# LPC11Uxx register map
File version: 7
CPU: CM0 r0p0, little endian, no MPU, no FPU, 2 interrupt priority bits
Registers are 32-bit, read-write, reset 0x0 unless marked. A register's access mark holds for its fields unless they carry their own. Offsets are from the block's base; [hi:lo] are bit positions; {n}, {i} and the like mark numbered series; 'fields as' and 'values as' point back to an identical list.

## IOCON — I/O configuration Modification
Base 0x40044000
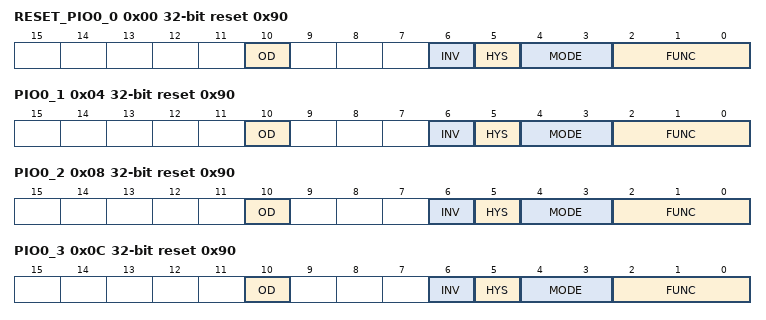
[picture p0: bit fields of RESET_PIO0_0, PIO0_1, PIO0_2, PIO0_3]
0x00 RESET_PIO0_0 reset 0x90 — I/O configuration for pin RESET/PIO0_0
  [10] OD — Open-drain mode.
    0=DISABLED; 1=OPEN_DRAIN (Open-drain mode enabled. This is not a true open-drain mode.)
  [6] INV — Invert input
    0=NOT_INVERTED (Input not inverted (HIGH on pin reads as 1, LOW on pin reads as 0).); 1=INVERTED (Input inverted (HIGH on pin reads as 0, LOW on pin reads as 1).)
  [5] HYS — Hysteresis.
    0=DISABLED; 1=ENABLED
  [4:3] MODE — Selects function mode (on-chip pull-up/pull-down resistor control).
    0=FLOATING (Inactive (no pull-down/pull-up resistor enabled).); 1=PULL_DOWN (Pull-down resistor enabled.); 2=PULL_UP (Pull-up resistor enabled.); 3=REPEATER (Repeater mode.)
  [2:0] FUNC — Selects pin function. Values 0x2 to 0x7 are reserved.
    0=RESET; 1=PIO0_0
0x04 PIO0_1 reset 0x90 — I/O configuration for pin PIO0_1/CLKOUT/CT32B0_MAT2/USB_FTOGGLE
  [10] OD — Open-drain mode.
    values as RESET_PIO0_0.OD
  [6] INV — Invert input
    values as RESET_PIO0_0.INV
  [5] HYS — Hysteresis.
    0=DISABLED; 1=ENABLED
  [4:3] MODE — Selects function mode (on-chip pull-up/pull-down resistor control).
    values as RESET_PIO0_0.MODE
  [2:0] FUNC — Selects pin function. Values 0x4 to 0x7 are reserved.
    0=PIO0_1; 1=CLKOUT; 2=CT32B0_MAT2; 3=USB_FTOGGLE
0x08 PIO0_2 reset 0x90 — I/O configuration for pin PIO0_2/SSEL0/CT16B0_CAP0
  [10] OD — Open-drain mode.
    values as RESET_PIO0_0.OD
  [6] INV — Invert input
    values as RESET_PIO0_0.INV
  [5] HYS — Hysteresis.
    0=DISABLED; 1=ENABLED
  [4:3] MODE — Selects function mode (on-chip pull-up/pull-down resistor control).
    values as RESET_PIO0_0.MODE
  [2:0] FUNC — Selects pin function. Values 0x3 to 0x7 are reserved.
    0=PIO0_2; 1=SSEL0; 2=CT16B0_CAP0
0x0C PIO0_3 reset 0x90 — I/O configuration for pin PIO0_3/USB_VBUS
  [10] OD — Open-drain mode.
    values as RESET_PIO0_0.OD
  [6] INV — Invert input
    values as RESET_PIO0_0.INV
  [5] HYS — Hysteresis.
    0=DISABLED; 1=ENABLED
  [4:3] MODE — Selects function mode (on-chip pull-up/pull-down resistor control).
    values as RESET_PIO0_0.MODE
  [2:0] FUNC — Selects pin function. Values 0x2 to 0x7 are reserved.
    0=PIO0_3; 1=USB_VBUS
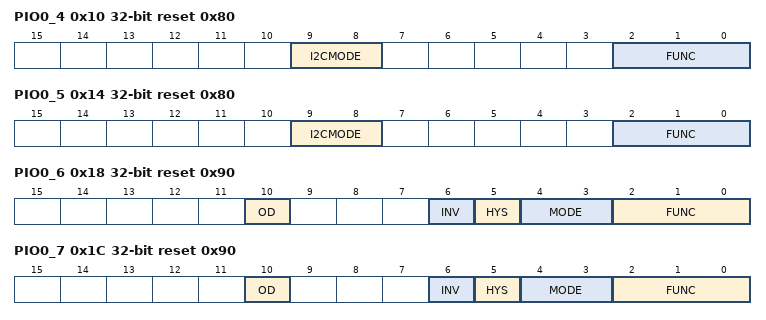
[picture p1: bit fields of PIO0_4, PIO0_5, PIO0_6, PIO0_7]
0x10 PIO0_4 reset 0x80 — I/O configuration for pin PIO0_4/SCL
  [9:8] I2CMODE — Selects I2C mode (see Section 7.3.8). Select Standard mode (I2CMODE = 00, default) or Standard I/O functionality (I2CMODE = 01) if the pin function is GPIO (FUNC = 000).
    0=STANDARD_MODE (Standard mode/ Fast-mode I2C.); 1=STANDARD_IO (Standard I/O functionality); 2=FAST_MODE_PLUS (Fast-mode Plus I2C)
  [2:0] FUNC — Selects pin function. Values 0x2 to 0x7 are reserved.
    0=PIO0_4 (PIO0_4 (open-drain pin).); 1=I2C_SCL (I2C SCL (open-drain pin).)
0x14 PIO0_5 reset 0x80 — I/O configuration for pin PIO0_5/SDA
  [9:8] I2CMODE — Selects I2C mode (see Section 7.3.8). Select Standard mode (I2CMODE = 00, default) or Standard I/O functionality (I2CMODE = 01) if the pin function is GPIO (FUNC = 000).
    values as PIO0_4.I2CMODE
  [2:0] FUNC — Selects pin function. Values 0x2 to 0x7 are reserved.
    0=PIO0_5 (PIO0_5 (open-drain pin).); 1=I2C_SDA (I2C SDA (open-drain pin).)
0x18 PIO0_6 reset 0x90 — I/O configuration for pin PIO0_6/USB_CONNECT/SCK0
  [10] OD — Open-drain mode.
    values as RESET_PIO0_0.OD
  [6] INV — Invert input
    values as RESET_PIO0_0.INV
  [5] HYS — Hysteresis.
    0=DISABLED; 1=ENABLED
  [4:3] MODE — Selects function mode (on-chip pull-up/pull-down resistor control).
    values as RESET_PIO0_0.MODE
  [2:0] FUNC — Selects pin function. Values 0x3 to 0x7 are reserved.
    0=PIO0_6; 1=USB_CONNECT; 2=SCK0
0x1C PIO0_7 reset 0x90 — I/O configuration for pin PIO0_7/CTS
  [10] OD — Open-drain mode.
    values as RESET_PIO0_0.OD
  [6] INV — Invert input
    values as RESET_PIO0_0.INV
  [5] HYS — Hysteresis.
    0=DISABLED; 1=ENABLED
  [4:3] MODE — Selects function mode (on-chip pull-up/pull-down resistor control).
    values as RESET_PIO0_0.MODE
  [2:0] FUNC — Selects pin function. Values 0x2 to 0x7 are reserved.
    0=PIO0_7; 1=CTS
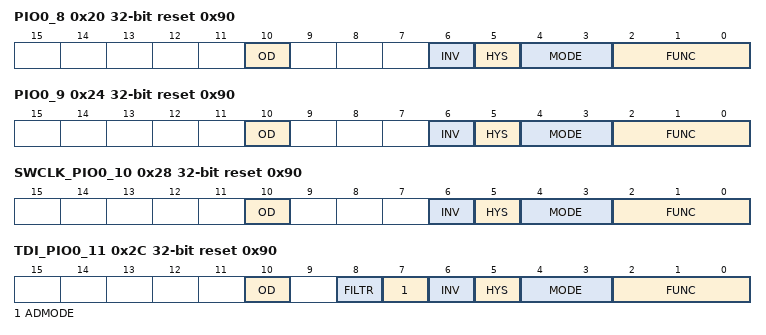
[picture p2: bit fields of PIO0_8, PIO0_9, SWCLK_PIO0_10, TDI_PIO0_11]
0x20 PIO0_8 reset 0x90 — I/O configuration for pin PIO0_8/MISO0/CT16B0_MAT0
  [10] OD — Open-drain mode.
    values as RESET_PIO0_0.OD
  [6] INV — Invert input
    values as RESET_PIO0_0.INV
  [5] HYS — Hysteresis.
    0=DISABLED; 1=ENABLED
  [4:3] MODE — Selects function mode (on-chip pull-up/pull-down resistor control).
    values as RESET_PIO0_0.MODE
  [2:0] FUNC — Selects pin function. Values 0x3 to 0x7 are reserved.
    0=PIO0_8; 1=MISO0; 2=CT16B0_MAT0
0x24 PIO0_9 reset 0x90 — I/O configuration for pin PIO0_9/MOSI0/CT16B0_MAT1
  [10] OD — Open-drain mode.
    values as RESET_PIO0_0.OD
  [6] INV — Invert input
    values as RESET_PIO0_0.INV
  [5] HYS — Hysteresis.
    0=DISABLED; 1=ENABLED
  [4:3] MODE — Selects function mode (on-chip pull-up/pull-down resistor control).
    values as RESET_PIO0_0.MODE
  [2:0] FUNC — Selects pin function. Values 0x3 to 0x7 are reserved.
    0=PIO0_9; 1=MOSI0; 2=CT16B0_MAT1
0x28 SWCLK_PIO0_10 reset 0x90 — I/O configuration for pin SWCLK/PIO0_10/ SCK0/CT16B0_MAT2
  [10] OD — Open-drain mode.
    values as RESET_PIO0_0.OD
  [6] INV — Invert input
    values as RESET_PIO0_0.INV
  [5] HYS — Hysteresis.
    0=DISABLED; 1=ENABLED
  [4:3] MODE — Selects function mode (on-chip pull-up/pull-down resistor control).
    values as RESET_PIO0_0.MODE
  [2:0] FUNC — Selects pin function. Values 0x4 to 0x7 are reserved.
    0=SWCLK; 1=PIO0_10; 2=SCK0; 3=CT16B0_MAT2
0x2C TDI_PIO0_11 reset 0x90 — I/O configuration for pin TDI/PIO0_11/AD0/CT32B0_MAT3
  [10] OD — Open-drain mode.
    values as RESET_PIO0_0.OD
  [8] FILTR — Selects 10 ns input glitch filter.
    0=ENABLED (Filter enabled.); 1=DISABLED (Filter disabled.)
  [7] ADMODE — Selects Analog/Digital mode.
    0=ANALOG (Analog input mode.); 1=DIGITAL (Digital functional mode.)
  [6] INV — Invert input
    values as RESET_PIO0_0.INV
  [5] HYS — Hysteresis.
    0=DISABLED; 1=ENABLED
  [4:3] MODE — Selects function mode (on-chip pull-up/pull-down resistor control).
    values as RESET_PIO0_0.MODE
  [2:0] FUNC — Selects pin function. Values 0x4 to 0x7 are reserved.
    0=TDI; 1=PIO0_11; 2=AD0; 3=CT32B0_MAT3
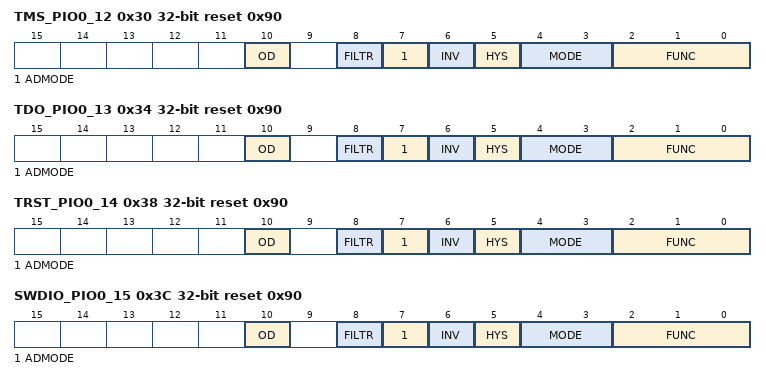
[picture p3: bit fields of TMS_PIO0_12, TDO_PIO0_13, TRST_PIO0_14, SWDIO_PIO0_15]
0x30 TMS_PIO0_12 reset 0x90 — I/O configuration for pin TMS/PIO0_12/AD1/CT32B1_CAP0
  [10] OD — Open-drain mode.
    values as RESET_PIO0_0.OD
  [8] FILTR — Selects 10 ns input glitch filter.
    0=ENABLED (Filter enabled.); 1=DISABLED (Filter disabled.)
  [7] ADMODE — Selects Analog/Digital mode.
    values as TDI_PIO0_11.ADMODE
  [6] INV — Invert input
    values as RESET_PIO0_0.INV
  [5] HYS — Hysteresis.
    0=DISABLED; 1=ENABLED
  [4:3] MODE — Selects function mode (on-chip pull-up/pull-down resistor control).
    values as RESET_PIO0_0.MODE
  [2:0] FUNC — Selects pin function. Values 0x4 to 0x7 are reserved.
    0=TMS; 1=PIO0_12; 2=AD1; 3=CT32B1_CAP0
0x34 TDO_PIO0_13 reset 0x90 — I/O configuration for pin TDO/PIO0_13/AD2/CT32B1_MAT0
  [10] OD — Open-drain mode.
    values as RESET_PIO0_0.OD
  [8] FILTR — Selects 10 ns input glitch filter.
    0=ENABLED (Filter enabled.); 1=DISABLED (Filter disabled.)
  [7] ADMODE — Selects Analog/Digital mode.
    values as TDI_PIO0_11.ADMODE
  [6] INV — Invert input
    values as RESET_PIO0_0.INV
  [5] HYS — Hysteresis.
    0=DISABLED; 1=ENABLED
  [4:3] MODE — Selects function mode (on-chip pull-up/pull-down resistor control).
    values as RESET_PIO0_0.MODE
  [2:0] FUNC — Selects pin function. Values 0x4 to 0x7 are reserved.
    0=TDO; 1=PIO0_13; 2=AD2; 3=CT32B1_MAT0
0x38 TRST_PIO0_14 reset 0x90 — I/O configuration for pin TRST/PIO0_14/AD3/CT32B1_MAT1
  [10] OD — Open-drain mode.
    values as RESET_PIO0_0.OD
  [8] FILTR — Selects 10 ns input glitch filter.
    0=ENABLED (Filter enabled.); 1=DISABLED (Filter disabled.)
  [7] ADMODE — Selects Analog/Digital mode.
    values as TDI_PIO0_11.ADMODE
  [6] INV — Invert input
    values as RESET_PIO0_0.INV
  [5] HYS — Hysteresis.
    0=DISABLED; 1=ENABLED
  [4:3] MODE — Selects function mode (on-chip pull-up/pull-down resistor control).
    values as RESET_PIO0_0.MODE
  [2:0] FUNC — Selects pin function. Values 0x4 to 0x7 are reserved.
    0=TRST; 1=PIO0_14; 2=AD3; 3=CT32B1_MAT1
0x3C SWDIO_PIO0_15 reset 0x90 — I/O configuration for pin SWDIO/PIO0_15/AD4/CT32B1_MAT2
  [10] OD — Open-drain mode.
    values as RESET_PIO0_0.OD
  [8] FILTR — Selects 10 ns input glitch filter.
    0=ENABLED (Filter enabled.); 1=DISABLED (Filter disabled.)
  [7] ADMODE — Selects Analog/Digital mode.
    values as TDI_PIO0_11.ADMODE
  [6] INV — Invert input
    values as RESET_PIO0_0.INV
  [5] HYS — Hysteresis.
    0=DISABLED; 1=ENABLED
  [4:3] MODE — Selects function mode (on-chip pull-up/pull-down resistor control).
    values as RESET_PIO0_0.MODE
  [2:0] FUNC — Selects pin function. Values 0x4 to 0x7 are reserved.
    0=SWDIO; 1=PIO0_15; 2=AD4; 3=CT32B1_MAT2
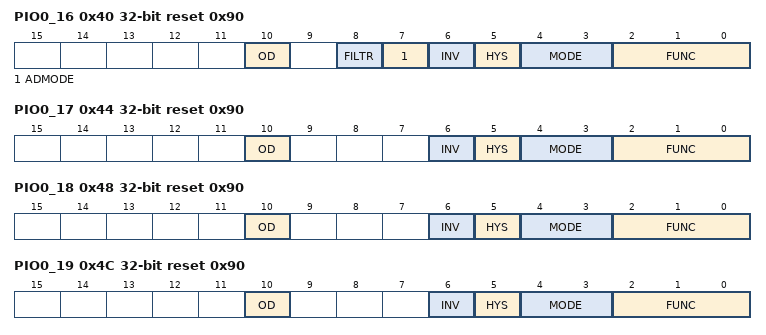
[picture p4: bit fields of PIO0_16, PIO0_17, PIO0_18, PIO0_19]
0x40 PIO0_16 reset 0x90 — I/O configuration for pin PIO0_16/AD5/CT32B1_MAT3/ WAKEUP
  [10] OD — Open-drain mode.
    values as RESET_PIO0_0.OD
  [8] FILTR — Selects 10 ns input glitch filter.
    0=ENABLED (Filter enabled.); 1=DISABLED (Filter disabled.)
  [7] ADMODE — Selects Analog/Digital mode.
    values as TDI_PIO0_11.ADMODE
  [6] INV — Invert input
    values as RESET_PIO0_0.INV
  [5] HYS — Hysteresis.
    0=DISABLED; 1=ENABLED
  [4:3] MODE — Selects function mode (on-chip pull-up/pull-down resistor control).
    values as RESET_PIO0_0.MODE
  [2:0] FUNC — Selects pin function. This pin functions as WAKEUP pin if the LPC11Uxx is in Deep power-down mode regardless of the value of FUNC. Values 0x3 to 0x7 are reserved.
    0=PIO0_16; 1=AD5; 2=CT32B1_MAT3
0x44 PIO0_17 reset 0x90 — I/O configuration for pin PIO0_17/RTS/CT32B0_CAP0/SCLK
  [10] OD — Open-drain mode.
    values as RESET_PIO0_0.OD
  [6] INV — Invert input
    values as RESET_PIO0_0.INV
  [5] HYS — Hysteresis.
    0=DISABLED; 1=ENABLED
  [4:3] MODE — Selects function mode (on-chip pull-up/pull-down resistor control).
    values as RESET_PIO0_0.MODE
  [2:0] FUNC — Selects pin function. Values 0x4 to 0x7 are reserved.
    0=PIO0_17; 1=RTS; 2=CT32B0_CAP0; 3=SCLK_UART_SYNCHRONO (SCLK (UART synchronous clock).)
0x48 PIO0_18 reset 0x90 — I/O configuration for pin PIO0_18/RXD/CT32B0_MAT0
  [10] OD — Open-drain mode.
    values as RESET_PIO0_0.OD
  [6] INV — Invert input
    values as RESET_PIO0_0.INV
  [5] HYS — Hysteresis.
    0=DISABLED; 1=ENABLED
  [4:3] MODE — Selects function mode (on-chip pull-up/pull-down resistor control).
    values as RESET_PIO0_0.MODE
  [2:0] FUNC — Selects pin function. Values 0x3 to 0x7 are reserved.
    0=PIO0_18; 1=RXD; 2=CT32B0_MAT0
0x4C PIO0_19 reset 0x90 — I/O configuration for pin PIO0_19/TXD/CT32B0_MAT1
  [10] OD — Open-drain mode.
    values as RESET_PIO0_0.OD
  [6] INV — Invert input
    values as RESET_PIO0_0.INV
  [5] HYS — Hysteresis.
    0=DISABLED; 1=ENABLED
  [4:3] MODE — Selects function mode (on-chip pull-up/pull-down resistor control).
    values as RESET_PIO0_0.MODE
  [2:0] FUNC — Selects pin function. Values 0x3 to 0x7 are reserved.
    0=PIO0_19; 1=TXD; 2=CT32B0_MAT1
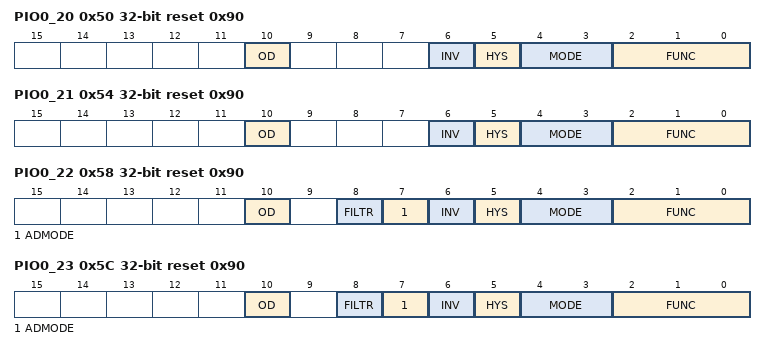
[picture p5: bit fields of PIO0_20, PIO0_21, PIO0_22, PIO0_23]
0x50 PIO0_20 reset 0x90 — I/O configuration for pin PIO0_20/CT16B1_CAP0
  [10] OD — Open-drain mode.
    values as RESET_PIO0_0.OD
  [6] INV — Invert input
    values as RESET_PIO0_0.INV
  [5] HYS — Hysteresis.
    0=DISABLED; 1=ENABLED
  [4:3] MODE — Selects function mode (on-chip pull-up/pull-down resistor control).
    values as RESET_PIO0_0.MODE
  [2:0] FUNC — Selects pin function. Values 0x2 to 0x7 are reserved.
    0=PIO0_20; 1=CT16B1_CAP0
0x54 PIO0_21 reset 0x90 — I/O configuration for pin PIO0_21/CT16B1_MAT0/MOSI1
  [10] OD — Open-drain mode.
    values as RESET_PIO0_0.OD
  [6] INV — Invert input
    values as RESET_PIO0_0.INV
  [5] HYS — Hysteresis.
    0=DISABLED; 1=ENABLED
  [4:3] MODE — Selects function mode (on-chip pull-up/pull-down resistor control).
    values as RESET_PIO0_0.MODE
  [2:0] FUNC — Selects pin function. Values 0x3 to 0x7 are reserved.
    0=PIO0_21; 1=CT16B1_MAT0; 2=MOSI1
0x58 PIO0_22 reset 0x90 — I/O configuration for pin PIO0_22/AD6/CT16B1_MAT1/MISO1
  [10] OD — Open-drain mode.
    values as RESET_PIO0_0.OD
  [8] FILTR — Selects 10 ns input glitch filter.
    0=ENABLED (Filter enabled.); 1=DISABLED (Filter disabled.)
  [7] ADMODE — Selects Analog/Digital mode.
    values as TDI_PIO0_11.ADMODE
  [6] INV — Invert input
    values as RESET_PIO0_0.INV
  [5] HYS — Hysteresis.
    0=DISABLED; 1=ENABLED
  [4:3] MODE — Selects function mode (on-chip pull-up/pull-down resistor control).
    values as RESET_PIO0_0.MODE
  [2:0] FUNC — Selects pin function. Values 0x4 to 0x7 are reserved.
    0=PIO0_22; 1=AD6; 2=CT16B1_MAT1; 3=MISO1
0x5C PIO0_23 reset 0x90 — I/O configuration for pin PIO0_23/AD7
  [10] OD — Open-drain mode.
    values as RESET_PIO0_0.OD
  [8] FILTR — Selects 10 ns input glitch filter.
    0=ENABLED (Filter enabled.); 1=DISABLED (Filter disabled.)
  [7] ADMODE — Selects Analog/Digital mode.
    values as TDI_PIO0_11.ADMODE
  [6] INV — Invert input
    values as RESET_PIO0_0.INV
  [5] HYS — Hysteresis.
    0=DISABLED; 1=ENABLED
  [4:3] MODE — Selects function mode (on-chip pull-up/pull-down resistor control).
    values as RESET_PIO0_0.MODE
  [2:0] FUNC — Selects pin function. Values 0x2 to 0x7 are reserved.
    0=PIO0_23; 1=AD7
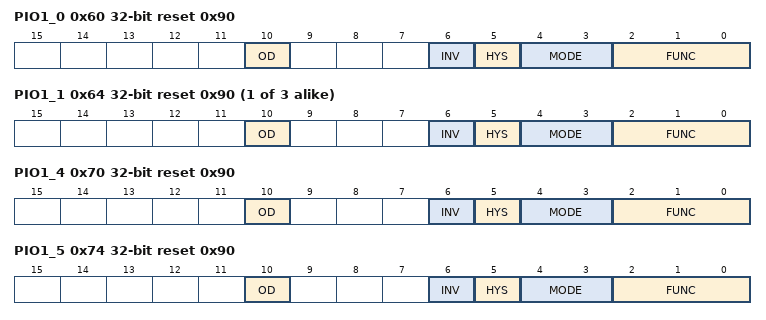
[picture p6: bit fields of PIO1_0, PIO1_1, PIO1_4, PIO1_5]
0x60 PIO1_0 reset 0x90 — I/O configuration for pin PIO1_0/CT32B1_MAT0
  [10] OD — Open-drain mode.
    0=DISABLED; 1=OPEN_DRAIN (Open-drain mode enabled. This is not a true open-drain mode. Input cannot be pulled up above VDD.)
  [6] INV — Invert input
    values as RESET_PIO0_0.INV
  [5] HYS — Hysteresis.
    0=DISABLED; 1=ENABLED
  [4:3] MODE — Selects function mode (on-chip pull-up/pull-down resistor control).
    values as RESET_PIO0_0.MODE
  [2:0] FUNC — Selects pin function. Values 0x2 to 0x7 are reserved.
    0=PIO1_0; 1=CT32B1_MAT1
{0x60+4i} PIO1_{i} reset 0x90 (i=1..3) — I/O configuration for pin PIO1_{i}/CT32B1_MAT{i}
  [10] OD — Open-drain mode.
    values as PIO1_0.OD
  [6] INV — Invert input
    values as RESET_PIO0_0.INV
  [5] HYS — Hysteresis.
    0=DISABLED; 1=ENABLED
  [4:3] MODE — Selects function mode (on-chip pull-up/pull-down resistor control).
    values as RESET_PIO0_0.MODE
  [2:0] FUNC — Selects pin function. Values 0x2 to 0x7 are reserved.
    0=PIO1_{i}; 1=CT32B1_MAT{i}
0x70 PIO1_4 reset 0x90 — I/O configuration for pin PIO1_4/CT32B1_CAP0
  [10] OD — Open-drain mode.
    values as PIO1_0.OD
  [6] INV — Invert input
    values as RESET_PIO0_0.INV
  [5] HYS — Hysteresis.
    0=DISABLED; 1=ENABLED
  [4:3] MODE — Selects function mode (on-chip pull-up/pull-down resistor control).
    values as RESET_PIO0_0.MODE
  [2:0] FUNC — Selects pin function. Values 0x2 to 0x7 are reserved.
    0=PIO1_4; 1=CT32B1_CAP0
0x74 PIO1_5 reset 0x90 — I/O configuration for pin PIO1_5/CT32B1_CAP1
  [10] OD — Open-drain mode.
    values as RESET_PIO0_0.OD
  [6] INV — Invert input
    values as RESET_PIO0_0.INV
  [5] HYS — Hysteresis.
    0=DISABLED; 1=ENABLED
  [4:3] MODE — Selects function mode (on-chip pull-up/pull-down resistor control).
    values as RESET_PIO0_0.MODE
  [2:0] FUNC — Selects pin function. Values 0x2 to 0x7 are reserved.
    0=PIO1_5; 1=CT32B1_CAP1
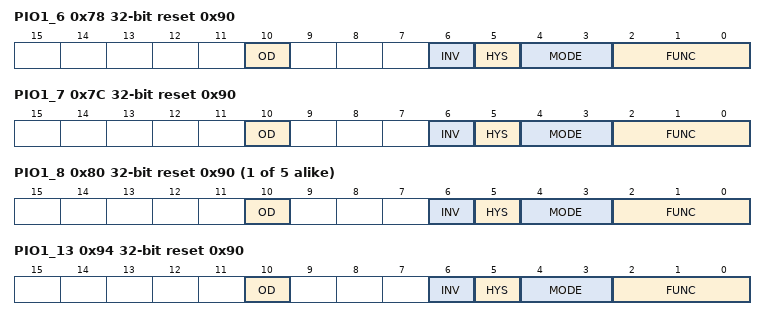
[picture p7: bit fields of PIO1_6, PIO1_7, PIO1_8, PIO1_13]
0x78 PIO1_6 reset 0x90 — I/O configuration for pin PIO1_6
  [10] OD — Open-drain mode.
    values as PIO1_0.OD
  [6] INV — Invert input
    values as RESET_PIO0_0.INV
  [5] HYS — Hysteresis.
    0=DISABLED; 1=ENABLED
  [4:3] MODE — Selects function mode (on-chip pull-up/pull-down resistor control).
    values as RESET_PIO0_0.MODE
  [2:0] FUNC — Selects pin function. Values 0x2 to 0x7 are reserved.
    0=PIO1_6
0x7C PIO1_7 reset 0x90 — I/O configuration for pin PIO1_7
  [10] OD — Open-drain mode.
    values as PIO1_0.OD
  [6] INV — Invert input
    values as RESET_PIO0_0.INV
  [5] HYS — Hysteresis.
    0=DISABLED; 1=ENABLED
  [4:3] MODE — Selects function mode (on-chip pull-up/pull-down resistor control).
    values as RESET_PIO0_0.MODE
  [2:0] FUNC — Selects pin function. Values 0x2 to 0x7 are reserved.
    0=PIO1_7
{0x60+4i} PIO1_{i} reset 0x90 (i=8..12) — I/O configuration for pin PIO1_{i}
  [10] OD — Open-drain mode.
    values as PIO1_0.OD
  [6] INV — Invert input
    values as RESET_PIO0_0.INV
  [5] HYS — Hysteresis.
    0=DISABLED; 1=ENABLED
  [4:3] MODE — Selects function mode (on-chip pull-up/pull-down resistor control).
    values as RESET_PIO0_0.MODE
  [2:0] FUNC — Selects pin function. Values 0x1 to 0x7 are reserved.
    0=PIO1_{i}
0x94 PIO1_13 reset 0x90 — I/O configuration for pin PIO1_13/DTR/CT16B0_MAT0/TXD
  [10] OD — Open-drain mode.
    values as RESET_PIO0_0.OD
  [6] INV — Invert input
    values as RESET_PIO0_0.INV
  [5] HYS — Hysteresis.
    0=DISABLED; 1=ENABLED
  [4:3] MODE — Selects function mode (on-chip pull-up/pull-down resistor control).
    values as RESET_PIO0_0.MODE
  [2:0] FUNC — Selects pin function. Values 0x4 to 0x7 are reserved.
    0=PIO1_13; 1=DTR; 2=CT16B0_MAT0; 3=TXD
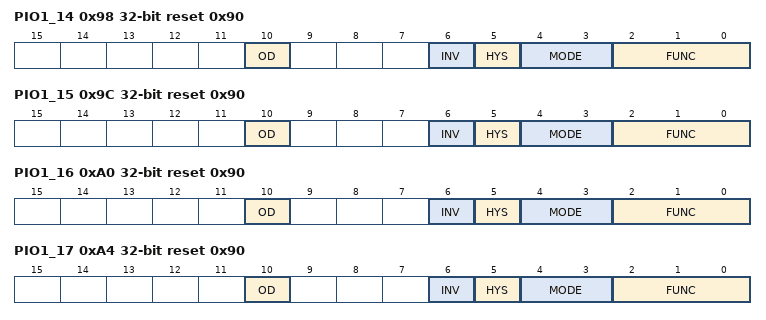
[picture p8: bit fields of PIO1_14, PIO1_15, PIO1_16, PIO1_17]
0x98 PIO1_14 reset 0x90 — I/O configuration for pin PIO1_14/DSR/CT16B0_MAT1/RXD
  [10] OD — Open-drain mode.
    values as RESET_PIO0_0.OD
  [6] INV — Invert input
    values as RESET_PIO0_0.INV
  [5] HYS — Hysteresis.
    0=DISABLED; 1=ENABLED
  [4:3] MODE — Selects function mode (on-chip pull-up/pull-down resistor control).
    values as RESET_PIO0_0.MODE
  [2:0] FUNC — Selects pin function. Values 0x4 to 0x7 are reserved.
    0=PIO1_14; 1=DSR; 2=CT16B0_MAT1; 3=RXD
0x9C PIO1_15 reset 0x90 — I/O configuration for pin PIO1_15/DCD/ CT16B0_MAT2/SCK1
  [10] OD — Open-drain mode.
    values as RESET_PIO0_0.OD
  [6] INV — Invert input
    values as RESET_PIO0_0.INV
  [5] HYS — Hysteresis.
    0=DISABLED; 1=ENABLED
  [4:3] MODE — Selects function mode (on-chip pull-up/pull-down resistor control).
    values as RESET_PIO0_0.MODE
  [2:0] FUNC — Selects pin function. Values 0x4 to 0x7 are reserved.
    0=PIO1_15; 1=DCD; 2=CT16B0_MAT2; 3=SCK1
0xA0 PIO1_16 reset 0x90 — I/O configuration for pin PIO1_16/RI/CT16B0_CAP0
  [10] OD — Open-drain mode.
    values as RESET_PIO0_0.OD
  [6] INV — Invert input
    values as RESET_PIO0_0.INV
  [5] HYS — Hysteresis.
    0=DISABLED; 1=ENABLED
  [4:3] MODE — Selects function mode (on-chip pull-up/pull-down resistor control).
    values as RESET_PIO0_0.MODE
  [2:0] FUNC — Selects pin function. Values 0x3 to 0x7 are reserved.
    0=PIO1_16; 1=RI; 2=CT16B0_CAP0
0xA4 PIO1_17 reset 0x90 — I/O configuration for PIO1_17/CT16B0_CAP1/RXD
  [10] OD — Open-drain mode.
    values as PIO1_0.OD
  [6] INV — Invert input
    values as RESET_PIO0_0.INV
  [5] HYS — Hysteresis.
    0=DISABLED; 1=ENABLED
  [4:3] MODE — Selects function mode (on-chip pull-up/pull-down resistor control).
    values as RESET_PIO0_0.MODE
  [2:0] FUNC — Selects pin function. Values 0x3 to 0x7 are reserved.
    0=PIO1_17; 1=CT16B0_CAP1; 2=RXD
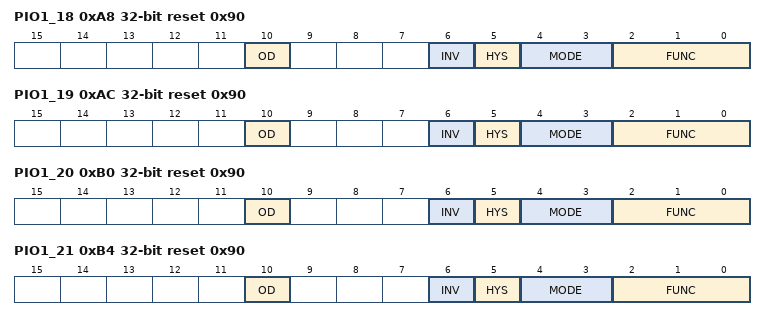
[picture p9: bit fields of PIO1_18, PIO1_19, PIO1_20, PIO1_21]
0xA8 PIO1_18 reset 0x90 — I/O configuration for PIO1_18/CT16B1_CAP1/TXD
  [10] OD — Open-drain mode.
    values as PIO1_0.OD
  [6] INV — Invert input
    values as RESET_PIO0_0.INV
  [5] HYS — Hysteresis.
    0=DISABLED; 1=ENABLED
  [4:3] MODE — Selects function mode (on-chip pull-up/pull-down resistor control).
    values as RESET_PIO0_0.MODE
  [2:0] FUNC — Selects pin function. Values 0x3 to 0x7 are reserved.
    0=PIO1_18; 1=CT16B1_CAP1; 2=TXD
0xAC PIO1_19 reset 0x90 — I/O configuration for pin PIO1_19/DTR/SSEL1
  [10] OD — Open-drain mode.
    values as RESET_PIO0_0.OD
  [6] INV — Invert input
    values as RESET_PIO0_0.INV
  [5] HYS — Hysteresis.
    0=DISABLED; 1=ENABLED
  [4:3] MODE — mode (on-chip pull-up/pull-down resistor control).
    values as RESET_PIO0_0.MODE
  [2:0] FUNC — Selects pin function. Values 0x3 to 0x7 are reserved.
    0=PIO1_19; 1=DTR; 2=SSEL1
0xB0 PIO1_20 reset 0x90 — I/O configuration for pin PIO1_20/DSR/SCK1
  [10] OD — Open-drain mode.
    values as RESET_PIO0_0.OD
  [6] INV — Invert input
    values as RESET_PIO0_0.INV
  [5] HYS — Hysteresis.
    0=DISABLED; 1=ENABLED
  [4:3] MODE — Selects function mode (on-chip pull-up/pull-down resistor control).
    values as RESET_PIO0_0.MODE
  [2:0] FUNC — Selects pin function. Values 0x3 to 0x7 are reserved.
    0=PIO1_20; 1=DSR; 2=SCK1
0xB4 PIO1_21 reset 0x90 — I/O configuration for pin PIO1_21/DCD/MISO1
  [10] OD — Open-drain mode.
    values as RESET_PIO0_0.OD
  [6] INV — Invert input
    values as RESET_PIO0_0.INV
  [5] HYS — Hysteresis.
    0=DISABLED; 1=ENABLED
  [4:3] MODE — Selects function mode (on-chip pull-up/pull-down resistor control).
    values as RESET_PIO0_0.MODE
  [2:0] FUNC — Selects pin function. Values 0x3 to 0x7 are reserved.
    0=PIO1_21; 1=DCD; 2=MISO1
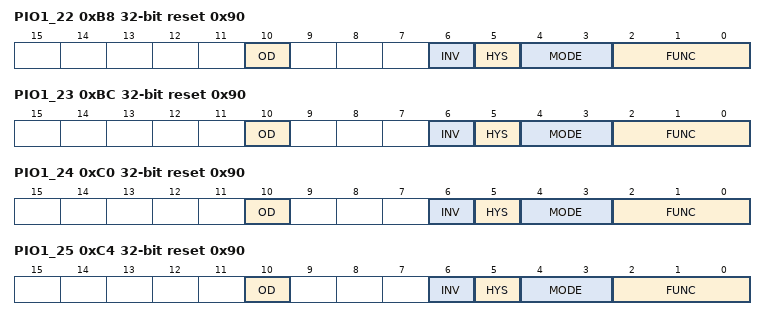
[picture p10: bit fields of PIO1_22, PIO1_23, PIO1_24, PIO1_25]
0xB8 PIO1_22 reset 0x90 — I/O configuration for pin PIO1_22/RI/MOSI1
  [10] OD — Open-drain mode.
    values as RESET_PIO0_0.OD
  [6] INV — Invert input
    values as RESET_PIO0_0.INV
  [5] HYS — Hysteresis.
    0=DISABLED; 1=ENABLED
  [4:3] MODE — Selects function mode (on-chip pull-up/pull-down resistor control).
    values as RESET_PIO0_0.MODE
  [2:0] FUNC — Selects pin function. Values 0x3 to 0x7 are reserved.
    0=PIO1_22; 1=RI; 2=MOSI1
0xBC PIO1_23 reset 0x90 — I/O configuration for pin PIO1_23/CT16B1_MAT1/SSEL1
  [10] OD — Open-drain mode.
    values as RESET_PIO0_0.OD
  [6] INV — Invert input
    values as RESET_PIO0_0.INV
  [5] HYS — Hysteresis.
    0=DISABLED; 1=ENABLED
  [4:3] MODE — Selects function mode (on-chip pull-up/pull-down resistor control).
    values as RESET_PIO0_0.MODE
  [2:0] FUNC — Selects pin function. Values 0x3 to 0x7 are reserved.
    0=PIO1_23; 1=CT16B1_MAT1; 2=SSEL1
0xC0 PIO1_24 reset 0x90 — I/O configuration for pin PIO1_24/ CT32B0_MAT0
  [10] OD — Open-drain mode.
    values as RESET_PIO0_0.OD
  [6] INV — Invert input
    values as RESET_PIO0_0.INV
  [5] HYS — Hysteresis.
    0=DISABLED; 1=ENABLED
  [4:3] MODE — Selects function mode (on-chip pull-up/pull-down resistor control).
    values as RESET_PIO0_0.MODE
  [2:0] FUNC — Selects pin function. Values 0x2 to 0x7 are reserved.
    0=PIO1_24; 1=CT32B0_MAT0
0xC4 PIO1_25 reset 0x90 — I/O configuration for pin PIO1_25/CT32B0_MAT1
  [10] OD — Open-drain mode.
    values as RESET_PIO0_0.OD
  [6] INV — Invert input
    values as RESET_PIO0_0.INV
  [5] HYS — Hysteresis.
    0=DISABLED; 1=ENABLED
  [4:3] MODE — Selects function mode (on-chip pull-up/pull-down resistor control).
    values as RESET_PIO0_0.MODE
  [2:0] FUNC — Selects pin function. Values 0x2 to 0x7 are reserved.
    0=PIO1_25; 1=CT32B0_MAT1
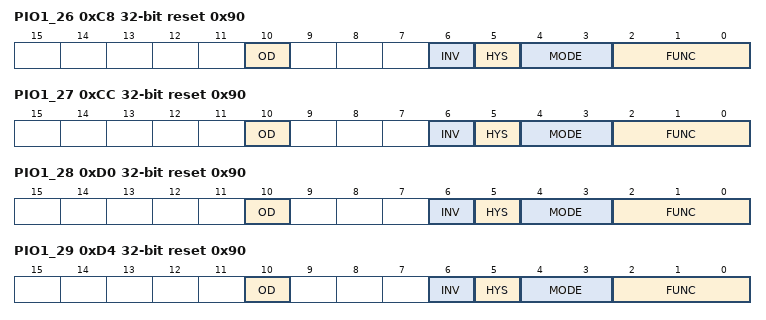
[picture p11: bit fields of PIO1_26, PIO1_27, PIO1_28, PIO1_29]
0xC8 PIO1_26 reset 0x90 — I/O configuration for pin PIO1_26/CT32B0_MAT2/ RXD
  [10] OD — Open-drain mode.
    values as RESET_PIO0_0.OD
  [6] INV — Invert input
    values as RESET_PIO0_0.INV
  [5] HYS — Hysteresis.
    0=DISABLED; 1=ENABLED
  [4:3] MODE — Selects function mode (on-chip pull-up/pull-down resistor control).
    values as RESET_PIO0_0.MODE
  [2:0] FUNC — Selects pin function. Values 0x3 to 0x7 are reserved.
    0=PIO1_26; 1=CT32B0_MAT2; 2=RXD
0xCC PIO1_27 reset 0x90 — I/O configuration for pin PIO1_27/CT32B0_MAT3/ TXD
  [10] OD — Open-drain mode.
    values as RESET_PIO0_0.OD
  [6] INV — Invert input
    values as RESET_PIO0_0.INV
  [5] HYS — Hysteresis.
    0=DISABLED; 1=ENABLED
  [4:3] MODE — Selects function mode (on-chip pull-up/pull-down resistor control).
    values as RESET_PIO0_0.MODE
  [2:0] FUNC — Selects pin function. Values 0x3 to 0x7 are reserved.
    0=PIO1_27; 1=CT32B0_MAT3; 2=TXD
0xD0 PIO1_28 reset 0x90 — I/O configuration for pin PIO1_28/CT32B0_CAP0/ SCLK
  [10] OD — Open-drain mode.
    values as RESET_PIO0_0.OD
  [6] INV — Invert input
    values as RESET_PIO0_0.INV
  [5] HYS — Hysteresis.
    0=DISABLED; 1=ENABLED
  [4:3] MODE — Selects function mode (on-chip pull-up/pull-down resistor control).
    values as RESET_PIO0_0.MODE
  [2:0] FUNC — Selects pin function. Values 0x3 to 0x7 are reserved.
    0=PIO1_28; 1=CT32B0_CAP0; 2=SCLK
0xD4 PIO1_29 reset 0x90 — I/O configuration for pin PIO1_29/SCK0/ CT32B0_CAP1
  [10] OD — Open-drain mode.
    values as RESET_PIO0_0.OD
  [6] INV — Invert input
    values as RESET_PIO0_0.INV
  [5] HYS — Hysteresis.
    0=DISABLED; 1=ENABLED
  [4:3] MODE — Selects function mode (on-chip pull-up/pull-down resistor control).
    values as RESET_PIO0_0.MODE
  [2:0] FUNC — Selects pin function. Values 0x3 to 0x7 are reserved.
    0=PIO1_29; 1=SCK0; 2=CT32B0_CAP1
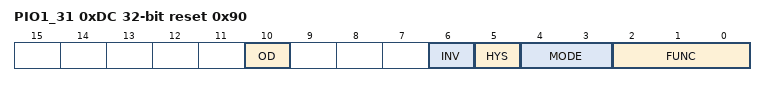
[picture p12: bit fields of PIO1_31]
0xDC PIO1_31 reset 0x90 — I/O configuration for pin PIO1_31
  [10] OD — Open-drain mode.
    values as RESET_PIO0_0.OD
  [6] INV — Invert input
    values as RESET_PIO0_0.INV
  [5] HYS — Hysteresis.
    0=DISABLED; 1=ENABLED
  [4:3] MODE — Selects function mode (on-chip pull-up/pull-down resistor control).
    values as RESET_PIO0_0.MODE
  [2:0] FUNC — Selects pin function. Values 0x1 to 0x7 are reserved.
    0=PIO1_31
